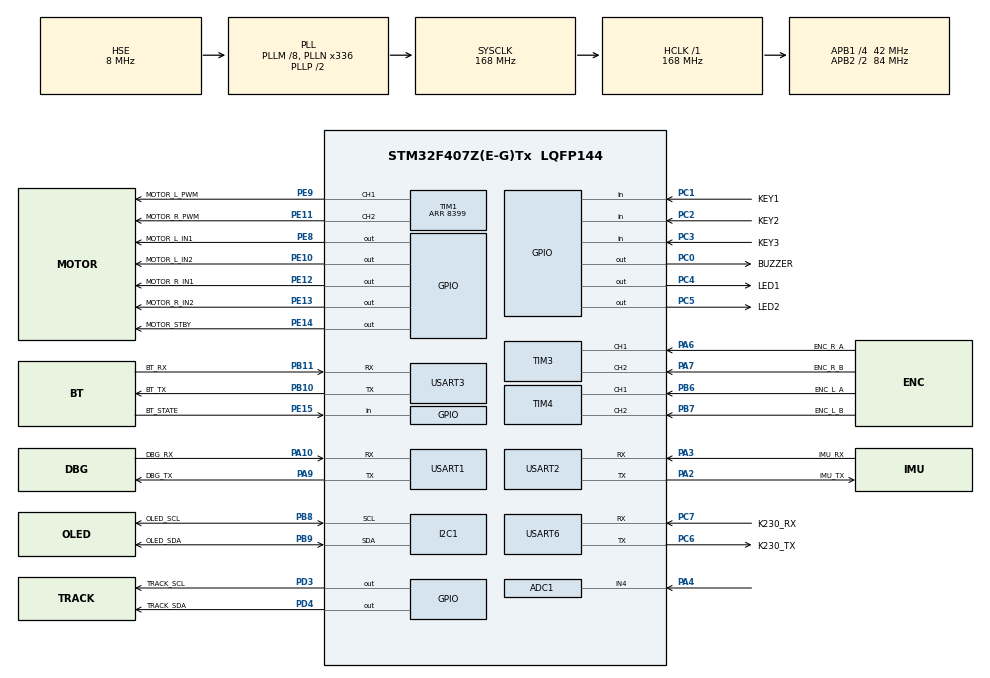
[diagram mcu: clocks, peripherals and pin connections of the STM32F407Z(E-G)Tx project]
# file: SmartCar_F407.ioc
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ADC1.Channel-0\#ChannelRegularConversion=ADC_CHANNEL_4
ADC1.NbrOfConversionFlag=1
ADC1.Rank-0\#ChannelRegularConversion=1
ADC1.SamplingTime-0\#ChannelRegularConversion=ADC_SAMPLETIME_144CYCLES
ADC1.master=1
Dma.Request0=USART6_RX
Dma.Request1=USART6_TX
Dma.Request2=USART3_RX
Dma.Request3=USART3_TX
Dma.Request4=USART1_RX
Dma.Request5=USART1_TX
Dma.Request6=USART2_RX
Dma.Request7=USART2_TX
Dma.USART1_RX.4.Direction=DMA_PERIPH_TO_MEMORY
Dma.USART1_RX.4.FIFOMode=DMA_FIFOMODE_DISABLE
Dma.USART1_RX.4.Instance=DMA2_Stream2
Dma.USART1_RX.4.MemDataAlignment=DMA_MDATAALIGN_BYTE
Dma.USART1_RX.4.MemInc=DMA_MINC_ENABLE
Dma.USART1_RX.4.Mode=DMA_CIRCULAR
Dma.USART1_RX.4.PeriphDataAlignment=DMA_PDATAALIGN_BYTE
Dma.USART1_RX.4.PeriphInc=DMA_PINC_DISABLE
Dma.USART1_RX.4.Priority=DMA_PRIORITY_HIGH
Dma.USART1_TX.5.Direction=DMA_MEMORY_TO_PERIPH
Dma.USART1_TX.5.FIFOMode=DMA_FIFOMODE_DISABLE
Dma.USART1_TX.5.Instance=DMA2_Stream7
Dma.USART1_TX.5.MemDataAlignment=DMA_MDATAALIGN_BYTE
Dma.USART1_TX.5.MemInc=DMA_MINC_ENABLE
Dma.USART1_TX.5.Mode=DMA_NORMAL
Dma.USART1_TX.5.PeriphDataAlignment=DMA_PDATAALIGN_BYTE
Dma.USART1_TX.5.PeriphInc=DMA_PINC_DISABLE
Dma.USART1_TX.5.Priority=DMA_PRIORITY_LOW
Dma.USART2_RX.6.Direction=DMA_PERIPH_TO_MEMORY
Dma.USART2_RX.6.FIFOMode=DMA_FIFOMODE_DISABLE
Dma.USART2_RX.6.Instance=DMA1_Stream5
Dma.USART2_RX.6.MemDataAlignment=DMA_MDATAALIGN_BYTE
Dma.USART2_RX.6.MemInc=DMA_MINC_ENABLE
Dma.USART2_RX.6.Mode=DMA_CIRCULAR
Dma.USART2_RX.6.PeriphDataAlignment=DMA_PDATAALIGN_BYTE
Dma.USART2_RX.6.PeriphInc=DMA_PINC_DISABLE
Dma.USART2_RX.6.Priority=DMA_PRIORITY_HIGH
Dma.USART2_TX.7.Direction=DMA_MEMORY_TO_PERIPH
Dma.USART2_TX.7.FIFOMode=DMA_FIFOMODE_DISABLE
Dma.USART2_TX.7.Instance=DMA1_Stream6
Dma.USART2_TX.7.MemDataAlignment=DMA_MDATAALIGN_BYTE
Dma.USART2_TX.7.MemInc=DMA_MINC_ENABLE
Dma.USART2_TX.7.Mode=DMA_NORMAL
Dma.USART2_TX.7.PeriphDataAlignment=DMA_PDATAALIGN_BYTE
Dma.USART2_TX.7.PeriphInc=DMA_PINC_DISABLE
Dma.USART2_TX.7.Priority=DMA_PRIORITY_LOW
Dma.USART3_RX.2.Direction=DMA_PERIPH_TO_MEMORY
Dma.USART3_RX.2.FIFOMode=DMA_FIFOMODE_DISABLE
Dma.USART3_RX.2.Instance=DMA1_Stream1
Dma.USART3_RX.2.MemDataAlignment=DMA_MDATAALIGN_BYTE
Dma.USART3_RX.2.MemInc=DMA_MINC_ENABLE
Dma.USART3_RX.2.Mode=DMA_CIRCULAR
Dma.USART3_RX.2.PeriphDataAlignment=DMA_PDATAALIGN_BYTE
Dma.USART3_RX.2.PeriphInc=DMA_PINC_DISABLE
Dma.USART3_RX.2.Priority=DMA_PRIORITY_HIGH
Dma.USART3_TX.3.Direction=DMA_MEMORY_TO_PERIPH
Dma.USART3_TX.3.FIFOMode=DMA_FIFOMODE_DISABLE
Dma.USART3_TX.3.Instance=DMA1_Stream3
Dma.USART3_TX.3.MemDataAlignment=DMA_MDATAALIGN_BYTE
Dma.USART3_TX.3.MemInc=DMA_MINC_ENABLE
Dma.USART3_TX.3.Mode=DMA_NORMAL
Dma.USART3_TX.3.PeriphDataAlignment=DMA_PDATAALIGN_BYTE
Dma.USART3_TX.3.PeriphInc=DMA_PINC_DISABLE
Dma.USART3_TX.3.Priority=DMA_PRIORITY_LOW
Dma.USART6_RX.0.Direction=DMA_PERIPH_TO_MEMORY
Dma.USART6_RX.0.FIFOMode=DMA_FIFOMODE_DISABLE
Dma.USART6_RX.0.Instance=DMA2_Stream1
Dma.USART6_RX.0.MemDataAlignment=DMA_MDATAALIGN_BYTE
Dma.USART6_RX.0.MemInc=DMA_MINC_ENABLE
Dma.USART6_RX.0.Mode=DMA_CIRCULAR
Dma.USART6_RX.0.PeriphDataAlignment=DMA_PDATAALIGN_BYTE
Dma.USART6_RX.0.PeriphInc=DMA_PINC_DISABLE
Dma.USART6_RX.0.Priority=DMA_PRIORITY_HIGH
Dma.USART6_TX.1.Direction=DMA_MEMORY_TO_PERIPH
Dma.USART6_TX.1.FIFOMode=DMA_FIFOMODE_DISABLE
Dma.USART6_TX.1.Instance=DMA2_Stream6
Dma.USART6_TX.1.MemDataAlignment=DMA_MDATAALIGN_BYTE
Dma.USART6_TX.1.MemInc=DMA_MINC_ENABLE
Dma.USART6_TX.1.Mode=DMA_NORMAL
Dma.USART6_TX.1.PeriphDataAlignment=DMA_PDATAALIGN_BYTE
Dma.USART6_TX.1.PeriphInc=DMA_PINC_DISABLE
Dma.USART6_TX.1.Priority=DMA_PRIORITY_LOW
FREERTOS.Tasks01=defaultTask,24,128,StartDefaultTask,Default,NULL,Dynamic,NULL,NULL
FREERTOS.configCHECK_FOR_STACK_OVERFLOW=2
FREERTOS.configTOTAL_HEAP_SIZE=24576
FREERTOS.configUSE_MALLOC_FAILED_HOOK=1
I2C1.I2C_Mode=I2C_Fast
Mcu.Family=STM32F4
Mcu.Name=STM32F407Z(E-G)Tx
Mcu.Package=LQFP144
NVIC.DMA1_Stream1_IRQn=true\:6\:0\:true\:false\:true\:true\:false\:true\:true
NVIC.DMA1_Stream3_IRQn=true\:7\:0\:true\:false\:true\:true\:false\:true\:true
NVIC.DMA1_Stream5_IRQn=true\:6\:0\:true\:false\:true\:true\:false\:true\:true
NVIC.DMA1_Stream6_IRQn=true\:7\:0\:true\:false\:true\:true\:false\:true\:true
NVIC.DMA2_Stream1_IRQn=true\:6\:0\:true\:false\:true\:true\:false\:true\:true
NVIC.DMA2_Stream2_IRQn=true\:6\:0\:true\:false\:true\:true\:false\:true\:true
NVIC.DMA2_Stream6_IRQn=true\:7\:0\:true\:false\:true\:true\:false\:true\:true
NVIC.DMA2_Stream7_IRQn=true\:7\:0\:true\:false\:true\:true\:false\:true\:true
NVIC.PriorityGroup=NVIC_PRIORITYGROUP_4
NVIC.TIM6_DAC_IRQn=true\:6\:0\:true\:false\:true\:true\:true\:true\:true
NVIC.TIM7_IRQn=true\:15\:0\:false\:false\:true\:false\:false\:true\:true
NVIC.TimeBase=TIM7_IRQn
NVIC.TimeBaseIP=TIM7
NVIC.USART1_IRQn=true\:7\:0\:true\:false\:true\:true\:true\:true\:true
NVIC.USART2_IRQn=true\:6\:0\:true\:false\:true\:true\:true\:true\:true
NVIC.USART3_IRQn=true\:6\:0\:true\:false\:true\:true\:true\:true\:true
NVIC.USART6_IRQn=true\:6\:0\:true\:false\:true\:true\:false\:true\:true
PA10.GPIO_Label=DBG_RX
PA10.Mode=Asynchronous
PA10.Signal=USART1_RX
PA13.Mode=Serial_Wire
PA13.Signal=SYS_JTMS-SWDIO
PA14.Mode=Serial_Wire
PA14.Signal=SYS_JTCK-SWCLK
PA2.GPIO_Label=IMU_TX
PA2.Mode=Asynchronous
PA2.Signal=USART2_TX
PA3.GPIO_Label=IMU_RX
PA3.Mode=Asynchronous
PA3.Signal=USART2_RX
PA4.Signal=ADCx_IN4
PA6.GPIO_Label=ENC_R_A
PA6.Signal=S_TIM3_CH1
PA7.GPIO_Label=ENC_R_B
PA7.Signal=S_TIM3_CH2
PA9.GPIO_Label=DBG_TX
PA9.Mode=Asynchronous
PA9.Signal=USART1_TX
PB10.GPIO_Label=BT_TX
PB10.Mode=Asynchronous
PB10.Signal=USART3_TX
PB11.GPIO_Label=BT_RX
PB11.Mode=Asynchronous
PB11.Signal=USART3_RX
PB6.GPIO_Label=ENC_L_A
PB6.Signal=S_TIM4_CH1
PB7.GPIO_Label=ENC_L_B
PB7.Signal=S_TIM4_CH2
PB8.GPIO_Label=OLED_SCL
PB8.Mode=I2C
PB8.Signal=I2C1_SCL
PB9.GPIO_Label=OLED_SDA
PB9.Mode=I2C
PB9.Signal=I2C1_SDA
PC0.GPIO_Label=BUZZER
PC0.Signal=GPIO_Output
PC1.GPIO_Label=KEY1
PC1.GPIO_PuPd=GPIO_PULLUP
PC1.Signal=GPIO_Input
PC2.GPIO_Label=KEY2
PC2.GPIO_PuPd=GPIO_PULLUP
PC2.Signal=GPIO_Input
PC3.GPIO_Label=KEY3
PC3.GPIO_PuPd=GPIO_PULLUP
PC3.Signal=GPIO_Input
PC4.GPIO_Label=LED1
PC4.Signal=GPIO_Output
PC5.GPIO_Label=LED2
PC5.Signal=GPIO_Output
PC6.GPIO_Label=K230_TX
PC6.Mode=Asynchronous
PC6.Signal=USART6_TX
PC7.GPIO_Label=K230_RX
PC7.Mode=Asynchronous
PC7.Signal=USART6_RX
PD3.GPIO_Label=TRACK_SCL
PD3.GPIO_ModeDefaultOutputPP=GPIO_MODE_OUTPUT_OD
PD3.GPIO_PuPd=GPIO_NOPULL
PD3.GPIO_Speed=GPIO_SPEED_FREQ_VERY_HIGH
PD3.PinState=GPIO_PIN_SET
PD3.Signal=GPIO_Output
PD4.GPIO_Label=TRACK_SDA
PD4.GPIO_ModeDefaultOutputPP=GPIO_MODE_OUTPUT_OD
PD4.GPIO_PuPd=GPIO_NOPULL
PD4.GPIO_Speed=GPIO_SPEED_FREQ_VERY_HIGH
PD4.PinState=GPIO_PIN_SET
PD4.Signal=GPIO_Output
PE10.GPIO_Label=MOTOR_L_IN2
PE10.GPIO_Speed=GPIO_SPEED_FREQ_MEDIUM
PE10.Signal=GPIO_Output
PE11.GPIO_Label=MOTOR_R_PWM
PE11.Signal=S_TIM1_CH2
PE12.GPIO_Label=MOTOR_R_IN1
PE12.GPIO_Speed=GPIO_SPEED_FREQ_MEDIUM
PE12.Signal=GPIO_Output
PE13.GPIO_Label=MOTOR_R_IN2
PE13.GPIO_Speed=GPIO_SPEED_FREQ_MEDIUM
PE13.Signal=GPIO_Output
PE14.GPIO_Label=MOTOR_STBY
PE14.GPIO_Speed=GPIO_SPEED_FREQ_MEDIUM
PE14.Signal=GPIO_Output
PE15.GPIO_Label=BT_STATE
PE15.GPIO_PuPd=GPIO_PULLDOWN
PE15.Signal=GPIO_Input
PE8.GPIO_Label=MOTOR_L_IN1
PE8.GPIO_Speed=GPIO_SPEED_FREQ_MEDIUM
PE8.Signal=GPIO_Output
PE9.GPIO_Label=MOTOR_L_PWM
PE9.Signal=S_TIM1_CH1
PH0-OSC_IN.Mode=HSE-External-Oscillator
PH0-OSC_IN.Signal=RCC_OSC_IN
PH1-OSC_OUT.Mode=HSE-External-Oscillator
PH1-OSC_OUT.Signal=RCC_OSC_OUT
ProjectManager.HeapSize=0x200
ProjectManager.StackSize=0x400
ProjectManager.TargetToolchain=MDK-ARM V5.32
RCC.48MHZClocksFreq_Value=84000000
RCC.AHBFreq_Value=168000000
RCC.APB1CLKDivider=RCC_HCLK_DIV4
RCC.APB1Freq_Value=42000000
RCC.APB1TimFreq_Value=84000000
RCC.APB2CLKDivider=RCC_HCLK_DIV2
RCC.APB2Freq_Value=84000000
RCC.APB2TimFreq_Value=168000000
RCC.CortexFreq_Value=168000000
RCC.HCLKFreq_Value=168000000
RCC.HSE_VALUE=8000000
RCC.HSI_VALUE=16000000
RCC.LSE_VALUE=32768
RCC.PLLM=8
RCC.PLLN=336
RCC.PLLSourceVirtual=RCC_PLLSOURCE_HSE
RCC.SYSCLKFreq_VALUE=168000000
RCC.SYSCLKSource=RCC_SYSCLKSOURCE_PLLCLK
RCC.VCOOutputFreq_Value=336000000
SH.ADCx_IN4.0=ADC1_IN4,IN4
SH.S_TIM1_CH1.0=TIM1_CH1,PWM Generation1 CH1
SH.S_TIM1_CH2.0=TIM1_CH2,PWM Generation2 CH2
SH.S_TIM3_CH1.0=TIM3_CH1,Encoder_Interface
SH.S_TIM3_CH2.0=TIM3_CH2,Encoder_Interface
SH.S_TIM4_CH1.0=TIM4_CH1,Encoder_Interface
SH.S_TIM4_CH2.0=TIM4_CH2,Encoder_Interface
TIM1.AutoReloadPreload=TIM_AUTORELOAD_PRELOAD_ENABLE
TIM1.Channel-PWM\ Generation1\ CH1=TIM_CHANNEL_1
TIM1.Channel-PWM\ Generation2\ CH2=TIM_CHANNEL_2
TIM1.Period=8399
TIM3.EncoderMode=TIM_ENCODERMODE_TI12
TIM4.EncoderMode=TIM_ENCODERMODE_TI12
TIM6.Period=49
TIM6.Prescaler=8399
USART1.VirtualMode=VM_ASYNC
USART2.VirtualMode=VM_ASYNC
USART3.VirtualMode=VM_ASYNC
USART6.VirtualMode=VM_ASYNC
VP_FREERTOS_VS_CMSIS_V2.Mode=CMSIS_V2
VP_SYS_VS_tim7.Mode=TIM7
VP_TIM1_VS_ClockSourceINT.Mode=Internal
VP_TIM6_VS_ClockSourceINT.Mode=Enable_Timer
board=custom

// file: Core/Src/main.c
/* USER CODE BEGIN Header */
/**
  ******************************************************************************
  * @file           : main.c
  * @brief          : Main program body
  ******************************************************************************
  * @attention
  *
  * Copyright (c) 2026 STMicroelectronics.
  * All rights reserved.
  *
	+
  0
  * This software is licensed under terms that can be found in the LICENSE file
  * in the root directory of this software component.
  * If no LICENSE file comes with this software, it is provided AS-IS.
  *
  ******************************************************************************
  */
/* USER CODE END Header */
#include "main.h"
#include "cmsis_os.h"
#include "adc.h"
#include "dma.h"
#include "i2c.h"
#include "tim.h"
#include "usart.h"
#include "gpio.h"

/* USER CODE BEGIN Includes */
#include "app_main.h"
/* USER CODE END Includes */

void SystemClock_Config(void);
void MX_FREERTOS_Init(void);

int main(void)
{

  /* MCU Configuration--------------------------------------------------------*/

  /* Reset of all peripherals, Initializes the Flash interface and the Systick. */
  HAL_Init();

  /* Configure the system clock */
  SystemClock_Config();

  /* Initialize all configured peripherals */
  MX_GPIO_Init();
  MX_DMA_Init();
  MX_TIM1_Init();
  MX_TIM3_Init();
  MX_TIM4_Init();
  MX_TIM6_Init();
  MX_USART1_UART_Init();
  MX_USART2_UART_Init();
  MX_USART3_UART_Init();
  MX_USART6_UART_Init();
  MX_ADC1_Init();
  MX_I2C1_Init();
  /* USER CODE BEGIN 2 */
  /* 业务层初始化：接管外设、加载参数、等 IMU 出第一帧。
   * 此时调度器还没启动，app_init() 内部只能用 HAL_Delay，不能用 vTaskDelay。 */
  app_init();
  /* USER CODE END 2 */

  /* Init scheduler */
  osKernelInitialize();  /* Call init function for freertos objects (in cmsis_os2.c) */
  MX_FREERTOS_Init();

  /* Start scheduler */
  osKernelStart();

  /* We should never get here as control is now taken by the scheduler */

  /* Infinite loop */
  while (1)
  {

  }
}

void SystemClock_Config(void)
{
  RCC_OscInitTypeDef RCC_OscInitStruct = {0};
  RCC_ClkInitTypeDef RCC_ClkInitStruct = {0};

  /** Configure the main internal regulator output voltage
  */
  __HAL_RCC_PWR_CLK_ENABLE();
  __HAL_PWR_VOLTAGESCALING_CONFIG(PWR_REGULATOR_VOLTAGE_SCALE1);

  /** Initializes the RCC Oscillators according to the specified parameters
  * in the RCC_OscInitTypeDef structure.
  */
  RCC_OscInitStruct.OscillatorType = RCC_OSCILLATORTYPE_HSE;
  RCC_OscInitStruct.HSEState = RCC_HSE_ON;
  RCC_OscInitStruct.PLL.PLLState = RCC_PLL_ON;
  RCC_OscInitStruct.PLL.PLLSource = RCC_PLLSOURCE_HSE;
  RCC_OscInitStruct.PLL.PLLM = 8;
  RCC_OscInitStruct.PLL.PLLN = 336;
  RCC_OscInitStruct.PLL.PLLP = RCC_PLLP_DIV2;
  RCC_OscInitStruct.PLL.PLLQ = 4;
  if (HAL_RCC_OscConfig(&RCC_OscInitStruct) != HAL_OK)
  {
    Error_Handler();
  }

  /** Initializes the CPU, AHB and APB buses clocks
  */
  RCC_ClkInitStruct.ClockType = RCC_CLOCKTYPE_HCLK|RCC_CLOCKTYPE_SYSCLK
                              |RCC_CLOCKTYPE_PCLK1|RCC_CLOCKTYPE_PCLK2;
  RCC_ClkInitStruct.SYSCLKSource = RCC_SYSCLKSOURCE_PLLCLK;
  RCC_ClkInitStruct.AHBCLKDivider = RCC_SYSCLK_DIV1;
  RCC_ClkInitStruct.APB1CLKDivider = RCC_HCLK_DIV4;
  RCC_ClkInitStruct.APB2CLKDivider = RCC_HCLK_DIV2;

  if (HAL_RCC_ClockConfig(&RCC_ClkInitStruct, FLASH_LATENCY_5) != HAL_OK)
  {
    Error_Handler();
  }
}

void HAL_TIM_PeriodElapsedCallback(TIM_HandleTypeDef *htim)
{
  /* USER CODE BEGIN Callback 0 */
  /* 5 ms 控制节拍：唤醒 ctrl 任务。TIM7 的 HAL_IncTick 仍在下面处理。 */
  if (htim->Instance == TIM6) { app_tim6_isr(); }
  /* USER CODE END Callback 0 */
  if (htim->Instance == TIM7)
  {
    HAL_IncTick();
  }
}

void Error_Handler(void)
{
  __disable_irq();
  while (1)
  {
  }
}

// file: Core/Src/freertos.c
/* USER CODE BEGIN Header */
/**
  ******************************************************************************
  * File Name          : freertos.c
  * Description        : Code for freertos applications
  ******************************************************************************
  * @attention
  *
  * Copyright (c) 2026 STMicroelectronics.
  * All rights reserved.
  *
  * This software is licensed under terms that can be found in the LICENSE file
  * in the root directory of this software component.
  * If no LICENSE file comes with this software, it is provided AS-IS.
  *
  ******************************************************************************
  */
/* USER CODE END Header */

#include "FreeRTOS.h"
#include "task.h"
#include "main.h"
#include "cmsis_os.h"

/* USER CODE BEGIN Includes */
#include "app_main.h"
/* USER CODE END Includes */

/* Definitions for defaultTask */
osThreadId_t defaultTaskHandle;
const osThreadAttr_t defaultTask_attributes = {
  .name = "defaultTask",
  .stack_size = 128 * 4,
  .priority = (osPriority_t) osPriorityNormal,
};

void StartDefaultTask(void *argument);

void MX_FREERTOS_Init(void); /* (MISRA C 2004 rule 8.1) */

/* Hook prototypes */
void vApplicationStackOverflowHook(xTaskHandle xTask, signed char *pcTaskName);
void vApplicationMallocFailedHook(void);

/* USER CODE BEGIN 4 */
void vApplicationStackOverflowHook(xTaskHandle xTask, signed char *pcTaskName)
{
   /* Run time stack overflow checking is performed if
   configCHECK_FOR_STACK_OVERFLOW is defined to 1 or 2. This hook function is
   called if a stack overflow is detected. */
}
/* USER CODE END 4 */

/* USER CODE BEGIN 5 */
void vApplicationMallocFailedHook(void)
{
   /* vApplicationMallocFailedHook() will only be called if
   configUSE_MALLOC_FAILED_HOOK is set to 1 in FreeRTOSConfig.h. It is a hook
   function that will get called if a call to pvPortMalloc() fails.
   pvPortMalloc() is called internally by the kernel whenever a task, queue,
   timer or semaphore is created. It is also called by various parts of the
   demo application. If heap_1.c or heap_2.c are used, then the size of the
   heap available to pvPortMalloc() is defined by configTOTAL_HEAP_SIZE in
   FreeRTOSConfig.h, and the xPortGetFreeHeapSize() API function can be used
   to query the size of free heap space that remains (although it does not
   provide information on how the remaining heap might be fragmented). */
}
/* USER CODE END 5 */

void MX_FREERTOS_Init(void) {

  /* Create the thread(s) */
  /* creation of defaultTask */
  defaultTaskHandle = osThreadNew(StartDefaultTask, NULL, &defaultTask_attributes);

  /* USER CODE BEGIN RTOS_THREADS */
  /* 用原生 FreeRTOS API 建任务（ctrl=5 / comm=3 / ui=1）。
   * 必须放在 osKernelStart() 之前，也就是这个位置。 */
  app_start();
  /* USER CODE END RTOS_THREADS */

}

void StartDefaultTask(void *argument)
{
  /* USER CODE BEGIN StartDefaultTask */
  /* ------------------------------------------------------------------
   * 这个 defaultTask 由 CubeMX 生成，优先级是 osPriorityNormal(=24)。
   * 我们自己用原生 FreeRTOS API 建任务（app_start()，优先级 5/3/1），
   * 24 > 5，控制任务会被永久饿死 —— 表现为"车一动不动、串口无输出、还不报错"。
   * 所以让它第一次运行就自我挂起，之后不再参与调度。
   * 注意：这段在 USER CODE 区内，重新生成代码不会丢。别删。
   * ------------------------------------------------------------------ */
  (void)argument;
  vTaskSuspend(NULL);

  /* Infinite loop */
  for(;;)
  {
    osDelay(1);
  }
  /* USER CODE END StartDefaultTask */
}
